# psoc4000s register map
Vendor: Cypress Semiconductor; Series: PSoC4000S; File version: 1.0
CPU: CM0PLUS r0p1, little endian, no MPU, no FPU, VTOR, 2 interrupt priority bits
Registers are 32-bit, read-write, reset 0x0 unless marked. A register's access mark holds for its fields unless they carry their own. Offsets are from the block's base; [hi:lo] are bit positions; {n}, {i} and the like mark numbered series.

## WCO — 32KHz Oscillator
Base 0x40070000
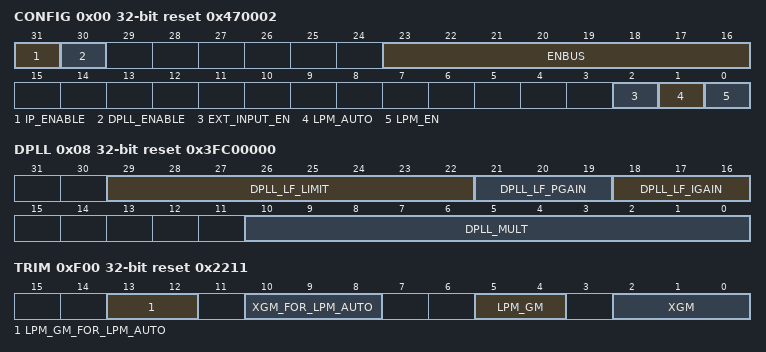
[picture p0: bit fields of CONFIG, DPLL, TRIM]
0x00 CONFIG reset 0x470002 — WCO Configuration Register
  [31] IP_ENABLE — Master enable for IP - disables both WCO and DPLL
  [30] DPLL_ENABLE — Enable DPLL operation. The Oscillator is specified to be stable after 500 ms thus the DPLL should be asserted no sooner than that after IP_ENABLE is set.
  [23:16] ENBUS — Test Mode Control bits enbus[7] - N/A enbus[6] - 1=enable both primary Beta Multipliers enbus[5] - N/A enbus[4] - N/A enbus[3] - Load Resistor Control enbus[2] - Load Resistor Control enbus[1] - Load Resistor Control enbus[0] - Load Resistor Control
  [2] EXT_INPUT_EN — Disables the load resistor and allows external clock input for pad_xin
  [1] LPM_AUTO — Automatically control low power mode (only relevant when LPM_EN=0): 0: Do not enter low power mode (LPM) in DeepSleep 1: Enter low power mode (LPM) in DeepSleep. The logic monitors !act_power_en to determine the device has entered DeepSleep.
  [0] LPM_EN — Force block into Low Power Mode: 0: Do not force low power mode (LPM) on 1: Force low power mode (LPM) on
0x04 STATUS ro — WCO Status Register
  [0] OUT_BLNK_A — Indicates that output has transitioned - This bit is intended for Test Mode Only and is not a reliable indicator.
0x08 DPLL reset 0x3FC00000 — WCO DPLL Register
  [29:22] DPLL_LF_LIMIT — Maximum IMO offset allowed (used to prevent DPLL dynamics from selecting an IMO frequency that the logic cannot support)
  [21:19] DPLL_LF_PGAIN — DPLL Loop Filter Proportionial Gain Setting 0x0 - 0.0625 0x1 - 0.125 0x2 - 0.25 0x3 - 0.5 0x4 - 1.0 0x5 - 2.0 0x6 - 4.0 0x7 - 8.0
  [18:16] DPLL_LF_IGAIN — DPLL Loop Filter Integral Gain Setting 0x0 - 0.0625 0x1 - 0.125 0x2 - 0.25 0x3 - 0.5 0x4 - 1.0 0x5 - 2.0 0x6 - 4.0 0x7 - 8.0
  [10:0] DPLL_MULT — Multiplier to determine IMO frequency in multiples of the WCO frequency Fimo = (DPLL_MULT + 1) * Fwco
0xF00 TRIM reset 0x2211 — WCO Trim Register
  [13:12] LPM_GM_FOR_LPM_AUTO — GM setting for LPM (bandwidth = DC/ms) - Used when WCO.LPM_AUTO=1 and in DeepSleep mode
  [10:8] XGM_FOR_LPM_AUTO — Amplifier GM setting - Used when WCO.LPM_AUTO=1 and in DeepSleep mode 0x0 - 3370 nA 0x1 - 2620 nA 0x2 - 2250 nA 0x3 - 1500 nA 0x4 - 1870 nA 0x5 - 1120 nA 0x6 - 750 nA 0x7 - 0 nA
  [5:4] LPM_GM — GM setting for LPM (bandwidth = DC/ms) - Used when WCO.LPM_AUTO=0 or when LPM_AUTO=1 and not in DeepSleep mode.
  [2:0] XGM — Amplifier GM setting - Used when WCO.LPM_AUTO=0 or when LPM_AUTO=1 and not in DeepSleep mode. 0x0 - 3370 nA 0x1 - 2620 nA 0x2 - 2250 nA 0x3 - 1500 nA 0x4 - 1870 nA 0x5 - 1120 nA 0x6 - 750 nA 0x7 - 0 nA

## LCD — LCD Controller Block
Base 0x400A0000
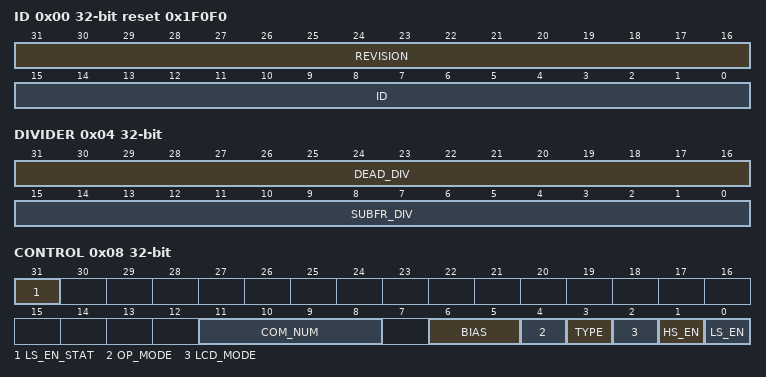
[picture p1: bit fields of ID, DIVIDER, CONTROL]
0x00 ID ro reset 0x1F0F0 — ID & Revision
  [31:16] REVISION — the version number is 0x0001
  [15:0] ID — the ID of LCD controller peripheral is 0xF0F0
0x04 DIVIDER — LCD Divider Register
  [31:16] DEAD_DIV — Length of the dead time period in cycles. When set to zero, no dead time period exists.
  [15:0] SUBFR_DIV — Input clock frequency divide value, to generate the 1/4 sub-frame period. The sub-frame period is 4*(SUBFR_DIV+1) cycles long.
0x08 CONTROL — LCD Configuration Register
  [31] LS_EN_STAT ro — LS enable status bit. This bit is a copy of LS_EN that is synchronized to the low speed clock domain and back to the system clock domain. Firmware can use this bit to observe whether LS_EN has taken effect in the low speed clock domain. Firmware should never change the configuration for the LS generator without ensuring this bit is 0. The following procedure should be followed to disable the LS generator: 1. If LS_EN=0 we are done. Exit the procedure. 2. Check that LS_EN_STAT=1. If not, wait until it is. This will catch the case of a recent enable (LS_EN=1) that has not taken effect yet. 3. Set LS_EN=0. 4. Wait until LS_EN_STAT=0.
  [11:8] COM_NUM — The number of COM connections minus 2. So: 0: 2 COM's 1: 3 COM's ... 13: 15 COM's 14: 16 COM's 15: undefined
  [6:5] BIAS — PWM bias selection
    0=HALF (1/2 Bias); 1=THIRD (1/3 Bias); 2=FOURTH (1/4 Bias (not supported by LS generator)); 3=FIFTH (1/5 Bias (not supported by LS generator))
  [4] OP_MODE — Driving mode configuration
    0=PWM (PWM Mode); 1=CORRELATION (Digital Correlation Mode)
  [3] TYPE — LCD driving waveform type configuration.
    0=TYPE_A (Type A - Each frame addresses each COM pin only once with a balanced (DC=0) waveform.); 1=TYPE_B (Type B - Each frame addresses each COM pin twice in sequence with a positive and negative waveform that together are balanced (DC=0).)
  [2] LCD_MODE — HS/LS Mode selection
    0=LS (Select Low Speed (32kHz) Generator (Works in Active, Sleep and DeepSleep power modes).); 1=HS (Select High Speed (system clock) Generator (Works in Active and Sleep power modes only).)
  [1] HS_EN — High speed (HS) generator enable 1: enable 0: disable
  [0] LS_EN — Low speed (LS) generator enable 1: enable 0: disable
{0x100+4i} DATA0[{i}] (i=0..7) — LCD Pin Data Registers
  [31:0] DATA — Bits [4i+3:4i] represent the pin data for pin [i] for COMS 1-4 (COM1 is lsb).
{0x200+4i} DATA1[{i}] (i=0..7) — LCD Pin Data Registers
  [31:0] DATA — Bits [4i+3:4i] represent the pin data for pin [i] for COMS 5-8 (COM5 is lsb).
{0x300+4i} DATA2[{i}] (i=0..7) — LCD Pin Data Registers
  [31:0] DATA — Bits [4i+3:4i] represent the pin data for pin [i] for COMS 9-12 (COM9 is lsb).
{0x400+4i} DATA3[{i}] (i=0..7) — LCD Pin Data Registers
  [31:0] DATA — Bits [4i+3:4i] represent the pin data for pin [i] for COMS 13-16 (COM13 is lsb).

## Notices in the file
Copyright 2016-2020 Cypress Semiconductor Corporation
Licensed under the Apache License, Version 2.0 (the "License");
you may not use this file except in compliance with the License.
You may obtain a copy of the License at
http://www.apache.org/licenses/LICENSE-2.0
Unless required by applicable law or agreed to in writing, software
distributed under the License is distributed on an "AS IS" BASIS,
WITHOUT WARRANTIES OR CONDITIONS OF ANY KIND, either express or implied.
See the License for the specific language governing permissions and
limitations under the License.
